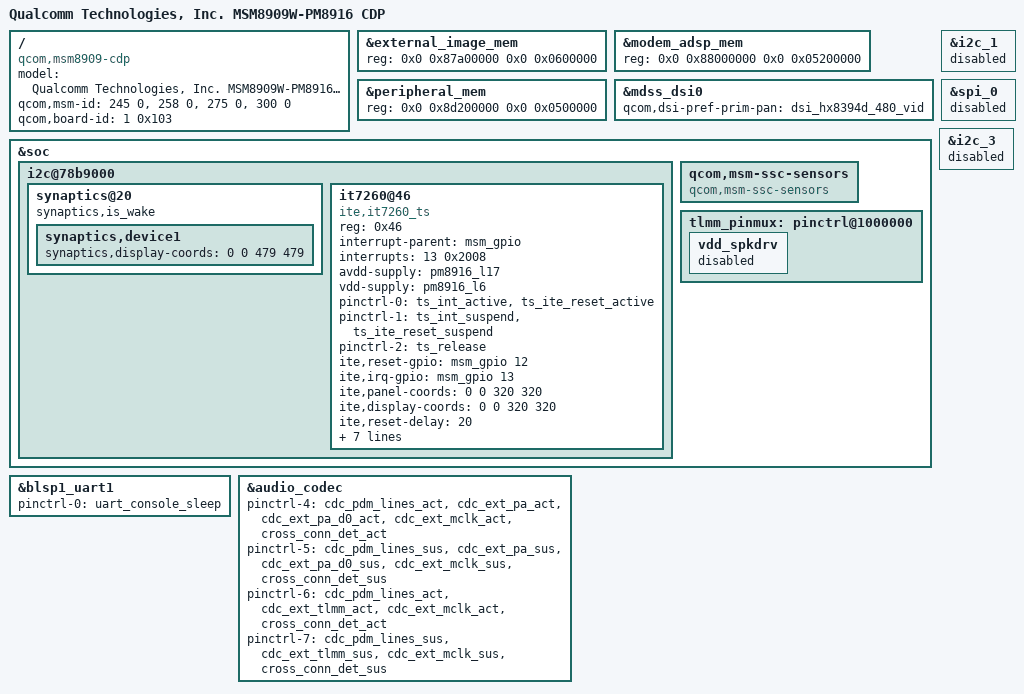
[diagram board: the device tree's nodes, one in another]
/*
 * Copyright (c) 2015, The Linux Foundation. All rights reserved.
 *
 * This program is free software; you can redistribute it and/or modify
 * it under the terms of the GNU General Public License version 2 and
 * only version 2 as published by the Free Software Foundation.
 *
 * This program is distributed in the hope that it will be useful,
 * but WITHOUT ANY WARRANTY; without even the implied warranty of
 * MERCHANTABILITY or FITNESS FOR A PARTICULAR PURPOSE.  See the
 * GNU General Public License for more details.
 */

/dts-v1/;

#include "msm8909-cdp.dtsi"
#include "msm8909w-gpu.dtsi"
#include "msm8909-pm8916-cdp.dtsi"
#include "msm8909w.dtsi"

/ {
	model = "Qualcomm Technologies, Inc. MSM8909W-PM8916 CDP";
	compatible = "qcom,msm8909-cdp", "qcom,msm8909", "qcom,cdp";
	qcom,msm-id =   <245 0>,
			<258 0>,
			<275 0>,
			<300 0>;
	qcom,board-id= <1 0x103>;
};

&external_image_mem {
	reg = <0x0 0x87a00000 0x0 0x0600000>;
};

&modem_adsp_mem {
	reg = <0x0 0x88000000 0x0 0x05200000>;
};

&peripheral_mem {
	reg = <0x0 0x8d200000 0x0 0x0500000>;
};

&mdss_dsi0 {
	qcom,dsi-pref-prim-pan = <&dsi_hx8394d_480_vid>;
};

&soc {
	i2c@78b9000 { /* BLSP1 QUP5 */

		/delete-node/ atmel_mxt_ts@4a;

		synaptics@20 {
			/delete-property/ synaptics,power-down;
			/delete-property/ synaptics,disable-gpios;
			synaptics,is_wake;
			synaptics,device1 {
				synaptics,display-coords = <0 0 479 479>;
			};
		};

		it7260@46 {
			compatible = "ite,it7260_ts";
			reg = <0x46>;
			interrupt-parent = <&msm_gpio>;
			interrupts = <13 0x2008>;
			avdd-supply = <&pm8916_l17>;
			vdd-supply = <&pm8916_l6>;
			/* pins used by touchscreen */
			pinctrl-names = "pmx_ts_active","pmx_ts_suspend","pmx_ts_release";
			pinctrl-0 = <&ts_int_active &ts_ite_reset_active>;
			pinctrl-1 = <&ts_int_suspend &ts_ite_reset_suspend>;
			pinctrl-2 = <&ts_release>;
			ite,reset-gpio = <&msm_gpio 12 0x00>;
			ite,irq-gpio = <&msm_gpio 13 0x2008>;
			ite,panel-coords = <0 0 320 320>;
			ite,display-coords = <0 0 320 320>;
			ite,reset-delay = <20>;
			ite,num-fingers = <2>;
			ite,wakeup;
			ite,palm-detect-en;
			ite,palm-detect-keycode = <142>;
			ite,fw-name = "it7260_fw.bin";
			ite,cfg-name = "it7260_cfg.bin";
			ite,avdd-lpm-cur = <3000>;
		};
	};

	qcom,msm-ssc-sensors {
		compatible = "qcom,msm-ssc-sensors";
	};

};

&i2c_1 {
	status = "disabled";
};

&spi_0 {
	status = "disabled";
};

&i2c_3 {
	status = "disabled";
};

&blsp1_uart1 {
	status = "ok";
	pinctrl-names = "default";
	pinctrl-0 = <&uart_console_sleep>;
};

&audio_codec {
	pinctrl-4 =     <&cdc_pdm_lines_act &cdc_ext_pa_act
			&cdc_ext_pa_d0_act &cdc_ext_mclk_act
			&cross_conn_det_act>;
	pinctrl-5 =     <&cdc_pdm_lines_sus &cdc_ext_pa_sus
			&cdc_ext_pa_d0_sus &cdc_ext_mclk_sus
			&cross_conn_det_sus>;
	pinctrl-6 =     <&cdc_pdm_lines_act &cdc_ext_tlmm_act
			&cdc_ext_mclk_act &cross_conn_det_act>;
	pinctrl-7 =     <&cdc_pdm_lines_sus &cdc_ext_tlmm_sus
			&cdc_ext_mclk_sus &cross_conn_det_sus>;
};

&soc {
	tlmm_pinmux: pinctrl@1000000 {
		vdd_spkdrv {
			status = "disabled";
		};
	};
};
